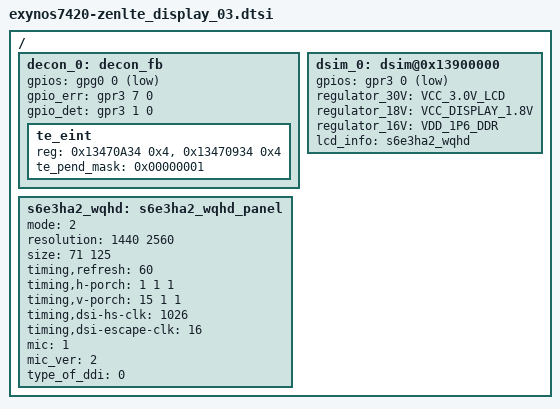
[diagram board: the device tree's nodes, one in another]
/*
 * SAMSUNG UNIVERSAL7420 board device tree source
 *
 * Copyright (c) 2014 Samsung Electronics Co., Ltd.
 *		http://www.samsung.com
 *
 * This program is free software; you can redistribute it and/or modify
 * it under the terms of the GNU General Public License version 2 as
 * published by the Free Software Foundation.
*/


/ {

	decon_0: decon_fb {
		/* EINT for TE */
		gpios = <&gpg0 0 0xf>;
		gpio_err = <&gpr3 7 0>;
		gpio_det = <&gpr3 1 0>;
		te_eint {
			reg = <0x13470A34 0x4>, <0x13470934 0x4>;
			te_pend_mask = <0x00000001>;
		};
	};


	dsim_0: dsim@0x13900000 {
		gpios = <&gpr3 0 0x1>;
		regulator_30V = "VCC_3.0V_LCD";
		regulator_18V = "VCC_DISPLAY_1.8V";
		regulator_16V = "VDD_1P6_DDR";
		lcd_info = <&s6e3ha2_wqhd>;
	};

	s6e3ha2_wqhd: s6e3ha2_wqhd_panel {
		mode = <2>;
		resolution = <1440 2560>;
		size = <71 125>;
		timing,refresh = <60>;
		timing,h-porch = <1 1 1>;
		timing,v-porch = <15 1 1>;
		timing,dsi-hs-clk = <1026>;
		timing,dsi-escape-clk = <16>;
		mic = <1>;
		mic_ver = <2>;
		type_of_ddi = <0>;
	};

};

